# nrf9120 register map
Vendor: Nordic Semiconductor; Series: nrf91; File version: 1
CPU: CM33 r0p4, little endian, MPU, FPU, 3 interrupt priority bits, 69 interrupts
Registers are 32-bit, read-write, reset 0x0 unless marked. A register's access mark holds for its fields unless they carry their own. Offsets are from the block's base; [hi:lo] are bit positions; lines under a group give offsets from that group; {n}, {i} and the like mark numbered series; 'fields as' and 'values as' point back to an identical list.

## REGULATORS_NS — Voltage regulators control 0
Base 0x40004000
Same registers: REGULATORS_S 0x50004000
0x500 SYSTEMOFF wo
  [0] SYSTEMOFF — Enable System OFF mode
    1=Enable System OFF mode
0x514 EXTPOFCON — External power failure warning configuration
  [0] POF — Enable or disable external power failure warning
    0=Disabled; 1=Enabled
0x578 DCDCEN — Enable DC/DC mode of the main voltage regulator.
  [0] DCDCEN — Enable DC/DC converter
    0=Disabled (DC/DC mode is disabled); 1=Enabled (DC/DC mode is enabled)

## CTRL_AP_PERI_S — Control access port
Base 0x50006000
0x400 MAILBOX group — Unspecified
  0x00 RXDATA ro — Data sent from the debugger to the CPU.
    [31:0] RXDATA — Data received from debugger
  0x04 RXSTATUS ro — This register shows a status that indicates if data sent from the debugger to the CPU has been read.
    [0] RXSTATUS — Status of data in register RXDATA
      0=No data pending in register RXDATA; 1=Data pending in register RXDATA
  0x80 TXDATA — Data sent from the CPU to the debugger.
    [31:0] TXDATA — Data sent to debugger
  0x84 TXSTATUS ro — This register shows a status that indicates if the data sent from the CPU to the debugger has been read.
    [0] TXSTATUS — Status of data in register TXDATA
      0=No data pending in register TXDATA; 1=Data pending in register TXDATA
0x500 ERASEPROTECT group — Unspecified
  0x00 LOCK rw-once — This register locks the ERASEPROTECT.DISABLE register from being written until next reset.
    [0] LOCK — Lock ERASEPROTECT.DISABLE register from being written until next reset
      0=Unlocked (Register ERASEPROTECT.DISABLE is writeable); 1=Locked (Register ERASEPROTECT.DISABLE is read-only)
  0x04 DISABLE rw-once — This register disables the ERASEPROTECT register and performs an ERASEALL operation.
    [31:0] KEY — The ERASEALL sequence is initiated if the value of the KEY fields are non-zero and the KEY fields match on both the CPU and debugger sides.

## DPPIC_NS — Distributed programmable peripheral interconnect controller 0
Base 0x40017000
Same registers: DPPIC_S 0x50017000
{0x0+8i} TASKS_CHG[{i}] (i=0..5) group — Channel group tasks
  0x00 EN wo — Description cluster: Enable channel group n
    [0] EN — Enable channel group n
      1=Trigger task
  0x04 DIS wo — Description cluster: Disable channel group n
    [0] DIS — Disable channel group n
      1=Trigger task
{0x80+8i} SUBSCRIBE_CHG[{i}] (i=0..5) group — Subscribe configuration for tasks
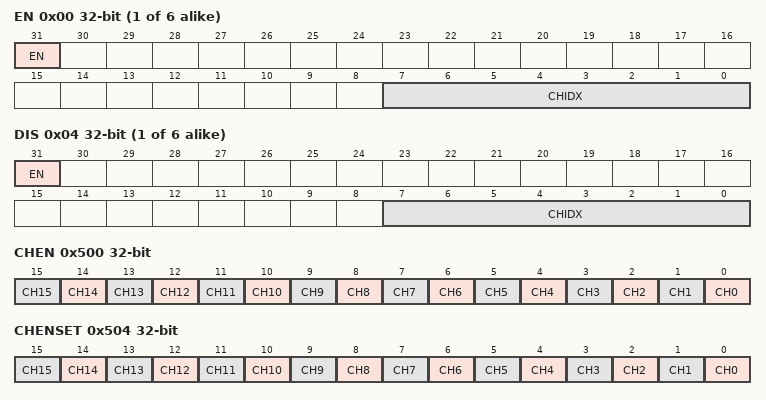
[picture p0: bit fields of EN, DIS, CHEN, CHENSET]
  0x00 EN — Description cluster: Subscribe configuration for task CHG[n].EN
    [31] EN
      0=Disabled (Disable subscription); 1=Enabled (Enable subscription)
    [7:0] CHIDX — DPPI channel that task CHG[n].EN will subscribe to
  0x04 DIS — Description cluster: Subscribe configuration for task CHG[n].DIS
    [31] EN
      values as SUBSCRIBE_CHG[0].EN.EN
    [7:0] CHIDX — DPPI channel that task CHG[n].DIS will subscribe to
0x500 CHEN — Channel enable register
  [all] fields
    0=Disabled (Disable channel); 1=Enabled (Enable channel)
  [n] CH{n} (n=0..15) — Enable or disable channel {n}
0x504 CHENSET write-1-sets — Channel enable set register
  [all] fields
    on read: 0=Disabled (Read: Channel disabled); 1=Enabled (Read: Channel enabled) | on write: 1=Set (Write: Enable channel)
  [n] CH{n} (n=0..15) — Channel {n} enable set register. Writing 0 has no effect.
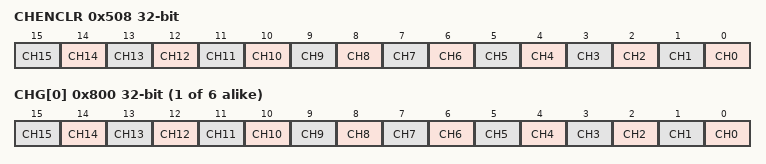
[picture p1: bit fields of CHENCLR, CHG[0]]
0x508 CHENCLR write-1-clears — Channel enable clear register
  [all] fields
    on read: 0=Disabled (Read: Channel disabled); 1=Enabled (Read: Channel enabled) | on write: 1=Clear (Write: Disable channel)
  [n] CH{n} (n=0..15) — Channel {n} enable clear register. Writing 0 has no effect.
{0x800+4i} CHG[{i}] (i=0..5) — Description collection: Channel group n Note: Writes to this register are ignored if either SUBSCRIBE_CHG[n].EN or SUBSCRIBE_CHG[n].DIS is enabled
  [all] fields
    0=Excluded; 1=Included
  [n] CH{n} (n=0..15) — Include or exclude channel {n}
